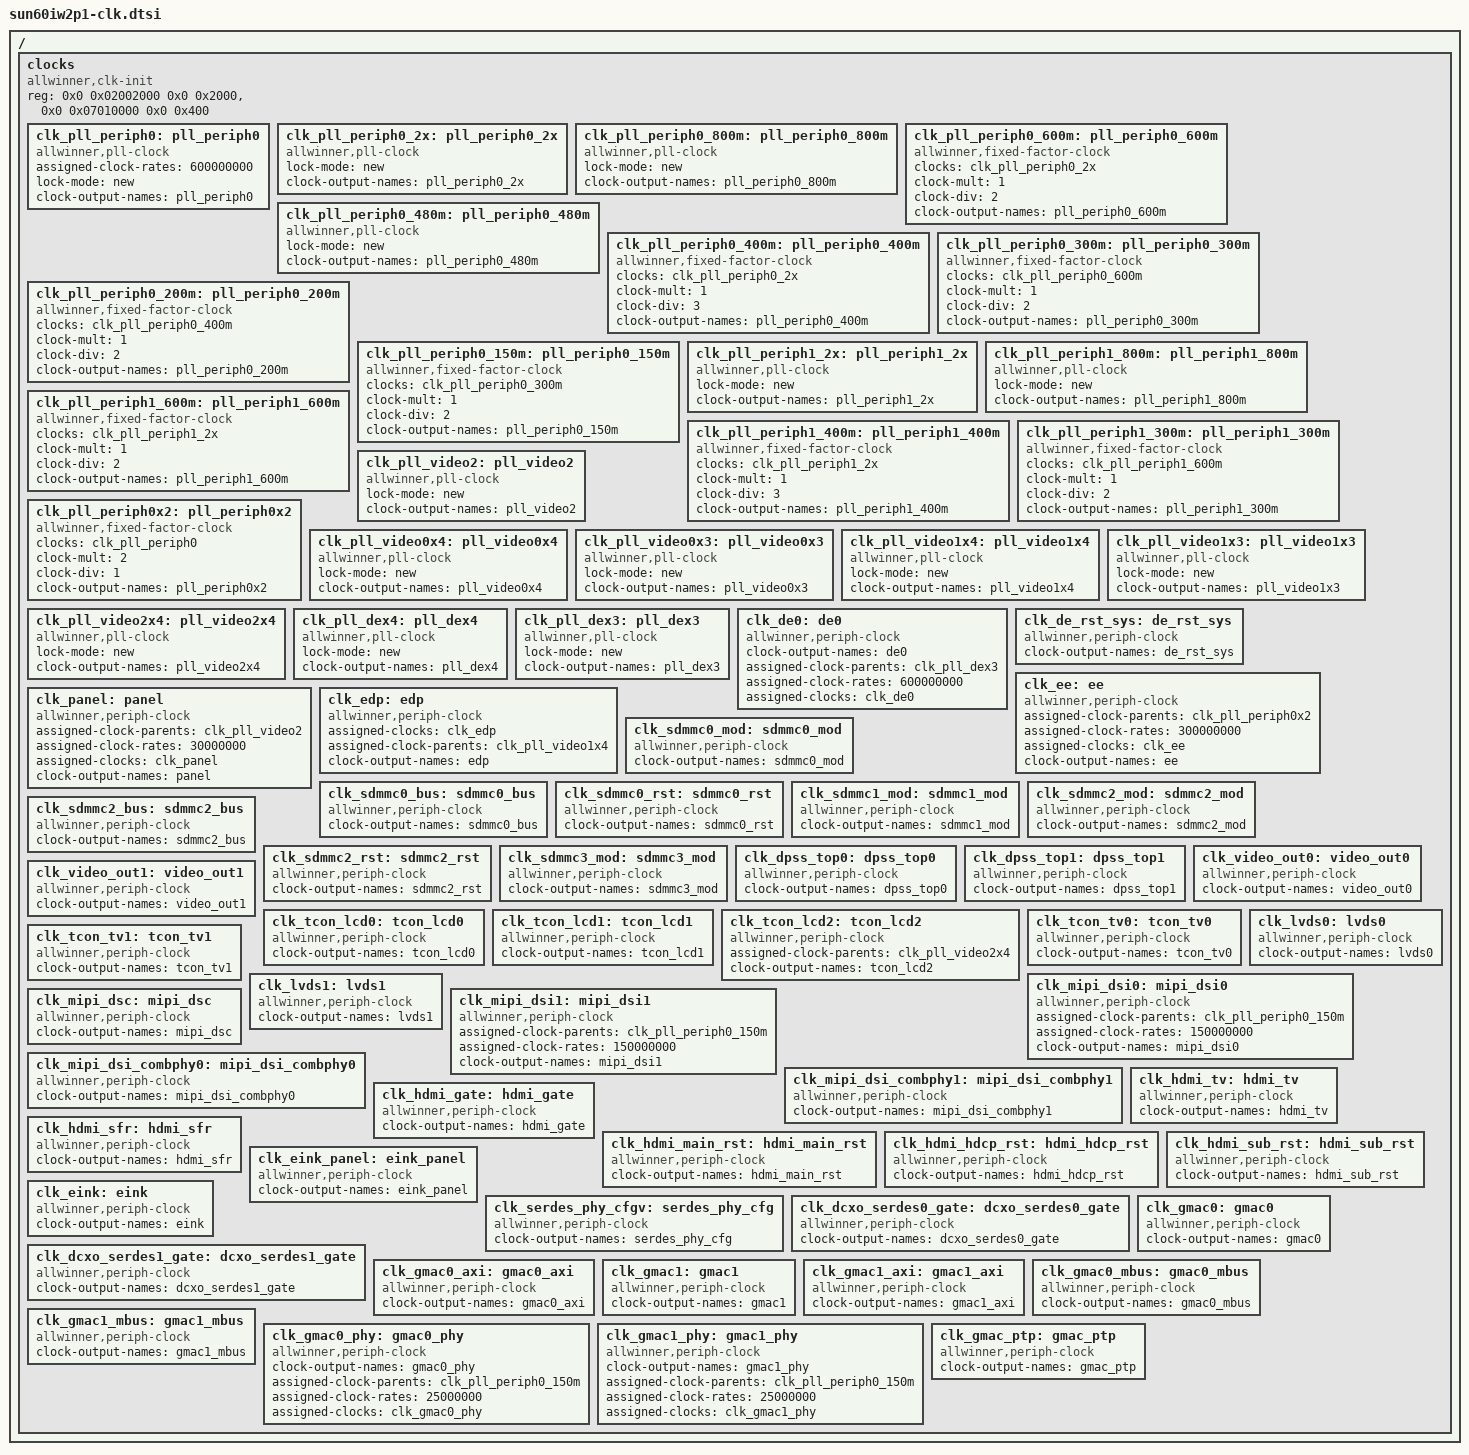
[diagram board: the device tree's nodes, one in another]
/{
clocks {
	compatible = "allwinner,clk-init";
	device_type = "clocks";
	#address-cells = <2>;
	#size-cells = <2>;
	ranges;
	reg = <0x0 0x02002000 0x0 0x2000>,	/*cpux space*/
	      <0x0 0x07010000 0x0 0x400>;	/*cpus space*/

		clk_pll_periph0: pll_periph0 {
			#clock-cells = <0>;
			compatible = "allwinner,pll-clock";
			assigned-clock-rates = <600000000>;
			lock-mode = "new";
			 clock-output-names = "pll_periph0";
		 };

		clk_pll_periph0_2x: pll_periph0_2x {
			#clock-cells = <0>;
			compatible = "allwinner,pll-clock";
			lock-mode = "new";
			clock-output-names = "pll_periph0_2x";
		};

		clk_pll_periph0_800m: pll_periph0_800m {
			#clock-cells = <0>;
			compatible = "allwinner,pll-clock";
			lock-mode = "new";
			clock-output-names = "pll_periph0_800m";
		};

		clk_pll_periph0_600m: pll_periph0_600m {
			#clock-cells = <0>;
			compatible = "allwinner,fixed-factor-clock";
			clocks = <&clk_pll_periph0_2x>;
			clock-mult = <1>;
			clock-div = <2>;
			clock-output-names = "pll_periph0_600m";
		};

		clk_pll_periph0_480m: pll_periph0_480m {
			#clock-cells = <0>;
			compatible = "allwinner,pll-clock";
			lock-mode = "new";
			clock-output-names = "pll_periph0_480m";
		};

		clk_pll_periph0_400m: pll_periph0_400m {
			#clock-cells = <0>;
			compatible = "allwinner,fixed-factor-clock";
			clocks = <&clk_pll_periph0_2x>;
			clock-mult = <1>;
			clock-div = <3>;
			clock-output-names = "pll_periph0_400m";
		};

		clk_pll_periph0_300m: pll_periph0_300m {
			#clock-cells = <0>;
			compatible = "allwinner,fixed-factor-clock";
			clocks = <&clk_pll_periph0_600m>;
			clock-mult = <1>;
			clock-div = <2>;
			clock-output-names = "pll_periph0_300m";
		};

		clk_pll_periph0_200m: pll_periph0_200m {
			#clock-cells = <0>;
			compatible = "allwinner,fixed-factor-clock";
			clocks = <&clk_pll_periph0_400m>;
			clock-mult = <1>;
			clock-div = <2>;
			clock-output-names = "pll_periph0_200m";
		};

		clk_pll_periph0_150m: pll_periph0_150m {
			#clock-cells = <0>;
			compatible = "allwinner,fixed-factor-clock";
			clocks = <&clk_pll_periph0_300m>;
			clock-mult = <1>;
			clock-div = <2>;
			clock-output-names = "pll_periph0_150m";
		};

		clk_pll_periph1_2x: pll_periph1_2x {
			#clock-cells = <0>;
			compatible = "allwinner,pll-clock";
			lock-mode = "new";
			clock-output-names = "pll_periph1_2x";
		};

		clk_pll_periph1_800m: pll_periph1_800m {
			#clock-cells = <0>;
			compatible = "allwinner,pll-clock";
			lock-mode = "new";
			clock-output-names = "pll_periph1_800m";
		};

		clk_pll_periph1_600m: pll_periph1_600m {
			#clock-cells = <0>;
			compatible = "allwinner,fixed-factor-clock";
			clocks = <&clk_pll_periph1_2x>;
			clock-mult = <1>;
			clock-div = <2>;
			clock-output-names = "pll_periph1_600m";
		};

		clk_pll_periph1_400m: pll_periph1_400m {
			#clock-cells = <0>;
			compatible = "allwinner,fixed-factor-clock";
			clocks = <&clk_pll_periph1_2x>;
			clock-mult = <1>;
			clock-div = <3>;
			clock-output-names = "pll_periph1_400m";
		};

		clk_pll_periph1_300m: pll_periph1_300m {
			#clock-cells = <0>;
			compatible = "allwinner,fixed-factor-clock";
			clocks = <&clk_pll_periph1_600m>;
			clock-mult = <1>;
			clock-div = <2>;
			clock-output-names = "pll_periph1_300m";
		};

		clk_pll_video2: pll_video2 {
			#clock-cells = <0>;
			compatible = "allwinner,pll-clock";
			lock-mode = "new";
			clock-output-names = "pll_video2";
		};

		clk_pll_periph0x2: pll_periph0x2 {
			#clock-cells = <0>;
			compatible = "allwinner,fixed-factor-clock";
			clocks = <&clk_pll_periph0>;
			clock-mult = <2>;
			clock-div = <1>;
			clock-output-names = "pll_periph0x2";
		};

		clk_pll_video0x4: pll_video0x4 {
			#clock-cells = <0>;
			compatible = "allwinner,pll-clock";
			lock-mode = "new";
			clock-output-names = "pll_video0x4";
		};

		clk_pll_video0x3: pll_video0x3 {
			#clock-cells = <0>;
			compatible = "allwinner,pll-clock";
			lock-mode = "new";
			clock-output-names = "pll_video0x3";
		};

		clk_pll_video1x4: pll_video1x4 {
			#clock-cells = <0>;
			compatible = "allwinner,pll-clock";
			lock-mode = "new";
			clock-output-names = "pll_video1x4";
		};

		clk_pll_video1x3: pll_video1x3 {
			#clock-cells = <0>;
			compatible = "allwinner,pll-clock";
			lock-mode = "new";
			clock-output-names = "pll_video1x3";
		};

		clk_pll_video2x4: pll_video2x4 {
			#clock-cells = <0>;
			compatible = "allwinner,pll-clock";
			lock-mode = "new";
			clock-output-names = "pll_video2x4";
		};

		clk_pll_dex4: pll_dex4 {
			#clock-cells = <0>;
			compatible = "allwinner,pll-clock";
			lock-mode = "new";
			clock-output-names = "pll_dex4";
		};

		clk_pll_dex3: pll_dex3 {
			#clock-cells = <0>;
			compatible = "allwinner,pll-clock";
			lock-mode = "new";
			clock-output-names = "pll_dex3";
		};

		clk_de0: de0 {
			#clock-cells = <0>;
			compatible = "allwinner,periph-clock";
			clock-output-names = "de0";
			assigned-clock-parents = <&clk_pll_dex3>;
			assigned-clock-rates = <600000000>;
			assigned-clocks = <&clk_de0>;
		};

		clk_de_rst_sys: de_rst_sys {
			#clock-cells = <0>;
			compatible = "allwinner,periph-clock";
			clock-output-names = "de_rst_sys";
		};

		clk_ee: ee {
			#clock-cells = <0>;
			compatible = "allwinner,periph-clock";
			assigned-clock-parents = <&clk_pll_periph0x2>;
			assigned-clock-rates = <300000000>;
			assigned-clocks = <&clk_ee>;
			clock-output-names = "ee";
		};

		clk_panel: panel {
			#clock-cells = <0>;
			compatible = "allwinner,periph-clock";
			assigned-clock-parents = <&clk_pll_video2>;
			assigned-clock-rates = <30000000>;
			assigned-clocks = <&clk_panel>;
			clock-output-names = "panel";
		};

		clk_edp: edp {
			#clock-cells = <0>;
			compatible = "allwinner,periph-clock";
			assigned-clocks = <&clk_edp>;
			assigned-clock-parents = <&clk_pll_video1x4>;
			clock-output-names = "edp";
		};

		clk_sdmmc0_mod: sdmmc0_mod {
			#clock-cells = <0>;
			compatible = "allwinner,periph-clock";
			clock-output-names = "sdmmc0_mod";
		};

		clk_sdmmc0_bus: sdmmc0_bus {
			#clock-cells = <0>;
			compatible = "allwinner,periph-clock";
			clock-output-names = "sdmmc0_bus";
		};

		clk_sdmmc0_rst: sdmmc0_rst {
			#clock-cells = <0>;
			compatible = "allwinner,periph-clock";
			clock-output-names = "sdmmc0_rst";
		};

		clk_sdmmc1_mod: sdmmc1_mod {
			#clock-cells = <0>;
			compatible = "allwinner,periph-clock";
			clock-output-names = "sdmmc1_mod";
		};

		clk_sdmmc2_mod: sdmmc2_mod {
			#clock-cells = <0>;
			compatible = "allwinner,periph-clock";
			clock-output-names = "sdmmc2_mod";
		};

		clk_sdmmc2_bus: sdmmc2_bus {
			#clock-cells = <0>;
			compatible = "allwinner,periph-clock";
			clock-output-names = "sdmmc2_bus";
		};

		clk_sdmmc2_rst: sdmmc2_rst {
			#clock-cells = <0>;
			compatible = "allwinner,periph-clock";
			clock-output-names = "sdmmc2_rst";
		};

		clk_sdmmc3_mod: sdmmc3_mod {
			#clock-cells = <0>;
			compatible = "allwinner,periph-clock";
			clock-output-names = "sdmmc3_mod";
		};

		clk_dpss_top0: dpss_top0 {
			#clock-cells = <0>;
			compatible = "allwinner,periph-clock";
			clock-output-names = "dpss_top0";
		};

		clk_dpss_top1: dpss_top1 {
			#clock-cells = <0>;
			compatible = "allwinner,periph-clock";
			clock-output-names = "dpss_top1";
		};

		clk_video_out0: video_out0 {
			#clock-cells = <0>;
			compatible = "allwinner,periph-clock";
			clock-output-names = "video_out0";
		};

		clk_video_out1: video_out1 {
			#clock-cells = <0>;
			compatible = "allwinner,periph-clock";
			clock-output-names = "video_out1";
		};

		clk_tcon_lcd0: tcon_lcd0 {
			#clock-cells = <0>;
			compatible = "allwinner,periph-clock";
			clock-output-names = "tcon_lcd0";
		};

		clk_tcon_lcd1: tcon_lcd1 {
			#clock-cells = <0>;
			compatible = "allwinner,periph-clock";
			clock-output-names = "tcon_lcd1";
		};

		clk_tcon_lcd2: tcon_lcd2 {
			#clock-cells = <0>;
			compatible = "allwinner,periph-clock";
			assigned-clock-parents = <&clk_pll_video2x4>;
			clock-output-names = "tcon_lcd2";
		};

		clk_tcon_tv0: tcon_tv0 {
			#clock-cells = <0>;
			compatible = "allwinner,periph-clock";
			clock-output-names = "tcon_tv0";
		};

		clk_tcon_tv1: tcon_tv1 {
			#clock-cells = <0>;
			compatible = "allwinner,periph-clock";
			clock-output-names = "tcon_tv1";
		};

		clk_lvds0: lvds0 {
			#clock-cells = <0>;
			compatible = "allwinner,periph-clock";
			clock-output-names = "lvds0";
		};

		clk_lvds1: lvds1 {
			#clock-cells = <0>;
			compatible = "allwinner,periph-clock";
			clock-output-names = "lvds1";
		};

		clk_mipi_dsi0: mipi_dsi0 {
			#clock-cells = <0>;
			compatible = "allwinner,periph-clock";
			assigned-clock-parents = <&clk_pll_periph0_150m>;
			assigned-clock-rates = <150000000>;
			clock-output-names = "mipi_dsi0";
		};

		clk_mipi_dsi1: mipi_dsi1 {
			#clock-cells = <0>;
			compatible = "allwinner,periph-clock";
			assigned-clock-parents = <&clk_pll_periph0_150m>;
			assigned-clock-rates = <150000000>;
			clock-output-names = "mipi_dsi1";
		};

		clk_mipi_dsc: mipi_dsc {
			#clock-cells = <0>;
			compatible = "allwinner,periph-clock";
			clock-output-names = "mipi_dsc";
		};

		clk_mipi_dsi_combphy0: mipi_dsi_combphy0 {
			#clock-cells = <0>;
			compatible = "allwinner,periph-clock";
			clock-output-names = "mipi_dsi_combphy0";
		};

		clk_mipi_dsi_combphy1: mipi_dsi_combphy1 {
			#clock-cells = <0>;
			compatible = "allwinner,periph-clock";
			clock-output-names = "mipi_dsi_combphy1";
		};

		clk_hdmi_tv: hdmi_tv {
			#clock-cells = <0>;
			compatible = "allwinner,periph-clock";
			clock-output-names = "hdmi_tv";
		};

		clk_hdmi_gate: hdmi_gate {
			#clock-cells = <0>;
			compatible = "allwinner,periph-clock";
			clock-output-names = "hdmi_gate";
		};

		clk_hdmi_sfr: hdmi_sfr {
			#clock-cells = <0>;
			compatible = "allwinner,periph-clock";
			clock-output-names = "hdmi_sfr";
		};

		clk_hdmi_main_rst: hdmi_main_rst {
			#clock-cells = <0>;
			compatible = "allwinner,periph-clock";
			clock-output-names = "hdmi_main_rst";
		};

		clk_hdmi_hdcp_rst: hdmi_hdcp_rst {
			#clock-cells = <0>;
			compatible = "allwinner,periph-clock";
			clock-output-names = "hdmi_hdcp_rst";
		};

		clk_hdmi_sub_rst: hdmi_sub_rst {
			#clock-cells = <0>;
			compatible = "allwinner,periph-clock";
			clock-output-names = "hdmi_sub_rst";
		};

		clk_eink_panel: eink_panel {
			#clock-cells = <0>;
			compatible = "allwinner,periph-clock";
			clock-output-names = "eink_panel";
		};

		clk_eink: eink {
			#clock-cells = <0>;
			compatible = "allwinner,periph-clock";
			clock-output-names = "eink";
		};

		clk_serdes_phy_cfgv: serdes_phy_cfg {
			#clock-cells = <0>;
			compatible = "allwinner,periph-clock";
			clock-output-names = "serdes_phy_cfg";
		};

		clk_dcxo_serdes0_gate: dcxo_serdes0_gate {
			#clock-cells = <0>;
			compatible = "allwinner,periph-clock";
			clock-output-names = "dcxo_serdes0_gate";
		};

		clk_dcxo_serdes1_gate: dcxo_serdes1_gate {
			#clock-cells = <0>;
			compatible = "allwinner,periph-clock";
			clock-output-names = "dcxo_serdes1_gate";
		};

		clk_gmac0: gmac0 {
			#clock-cells = <0>;
			compatible = "allwinner,periph-clock";
			clock-output-names = "gmac0";
		};

		clk_gmac0_axi: gmac0_axi {
			#clock-cells = <0>;
			compatible = "allwinner,periph-clock";
			clock-output-names = "gmac0_axi";
		};

		clk_gmac1: gmac1 {
			#clock-cells = <0>;
			compatible = "allwinner,periph-clock";
			clock-output-names = "gmac1";
		};

		clk_gmac1_axi: gmac1_axi {
			#clock-cells = <0>;
			compatible = "allwinner,periph-clock";
			clock-output-names = "gmac1_axi";
		};

		clk_gmac0_mbus: gmac0_mbus {
			#clock-cells = <0>;
			compatible = "allwinner,periph-clock";
			clock-output-names = "gmac0_mbus";
		};

		clk_gmac1_mbus: gmac1_mbus {
			#clock-cells = <0>;
			compatible = "allwinner,periph-clock";
			clock-output-names = "gmac1_mbus";
		};

		clk_gmac0_phy: gmac0_phy {
			#clock-cells = <0>;
			compatible = "allwinner,periph-clock";
			clock-output-names = "gmac0_phy";
			assigned-clock-parents = <&clk_pll_periph0_150m>;
			assigned-clock-rates = <25000000>;
			assigned-clocks = <&clk_gmac0_phy>;

		};

		clk_gmac1_phy: gmac1_phy {
			#clock-cells = <0>;
			compatible = "allwinner,periph-clock";
			clock-output-names = "gmac1_phy";
			assigned-clock-parents = <&clk_pll_periph0_150m>;
			assigned-clock-rates = <25000000>;
			assigned-clocks = <&clk_gmac1_phy>;
		};

		clk_gmac_ptp: gmac_ptp {
			#clock-cells = <0>;
			compatible = "allwinner,periph-clock";
			clock-output-names = "gmac_ptp";
		};
	};
};
